# PIC32MX695F512L register map
Registers are 32-bit, access not given, reset 0x0 unless marked. A register's access mark holds for its fields unless they carry their own. Offsets are from the block's base; [hi:lo] are bit positions; 'fields as' and 'values as' point back to an identical list.

## CVR — CVR peripheral
Base 0xBF809800
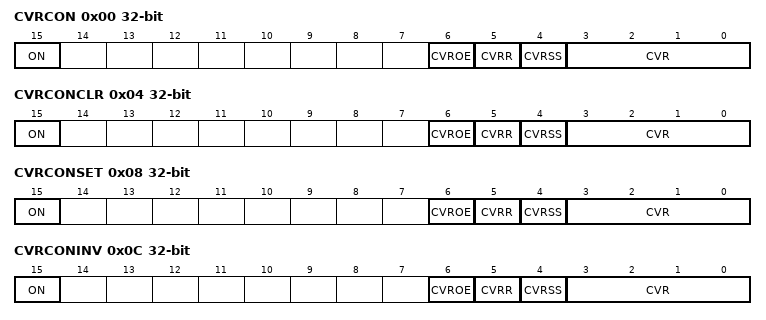
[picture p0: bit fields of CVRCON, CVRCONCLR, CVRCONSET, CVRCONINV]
0x00 CVRCON
  [15] ON, [6] CVROE, [5] CVRR, [4] CVRSS, [3:0] CVR
0x04 CVRCONCLR
  [15] ON, [6] CVROE, [5] CVRR, [4] CVRSS, [3:0] CVR
0x08 CVRCONSET
  [15] ON, [6] CVROE, [5] CVRR, [4] CVRSS, [3:0] CVR
0x0C CVRCONINV
  [15] ON, [6] CVROE, [5] CVRR, [4] CVRSS, [3:0] CVR

## CMP1 — CMP1 peripheral
Base 0xBF80A000
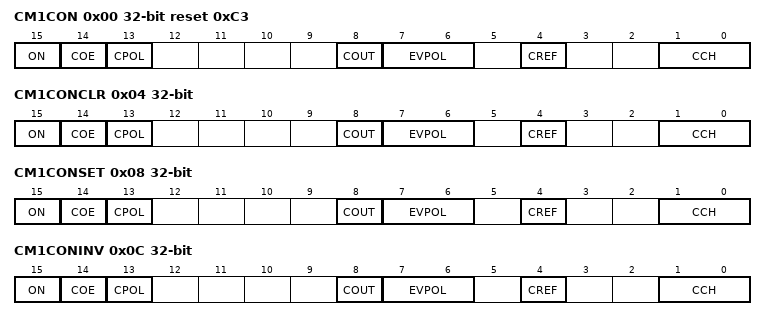
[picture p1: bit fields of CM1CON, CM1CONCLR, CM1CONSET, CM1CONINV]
0x00 CM1CON reset 0xC3
  [15] ON, [14] COE, [13] CPOL, [8] COUT, [7:6] EVPOL, [4] CREF, [1:0] CCH
0x04 CM1CONCLR
  fields as CM1CON
0x08 CM1CONSET
  fields as CM1CON
0x0C CM1CONINV
  fields as CM1CON

## CMP2 — CMP2 peripheral
Base 0xBF80A010
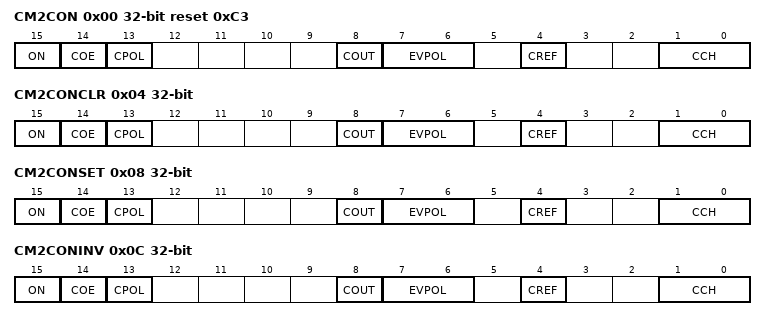
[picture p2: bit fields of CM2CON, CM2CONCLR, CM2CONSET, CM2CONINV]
0x00 CM2CON reset 0xC3
  [15] ON, [14] COE, [13] CPOL, [8] COUT, [7:6] EVPOL, [4] CREF, [1:0] CCH
0x04 CM2CONCLR
  fields as CM2CON
0x08 CM2CONSET
  fields as CM2CON
0x0C CM2CONINV
  fields as CM2CON

## CMP — CMP peripheral
Base 0xBF80A060
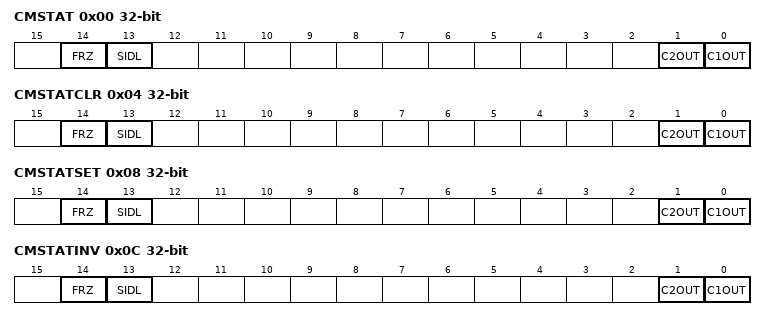
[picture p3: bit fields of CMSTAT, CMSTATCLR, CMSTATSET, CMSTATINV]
0x00 CMSTAT
  [14] FRZ, [13] SIDL, [1] C2OUT, [0] C1OUT
0x04 CMSTATCLR
  [14] FRZ, [13] SIDL, [1] C2OUT, [0] C1OUT
0x08 CMSTATSET
  [14] FRZ, [13] SIDL, [1] C2OUT, [0] C1OUT
0x0C CMSTATINV
  [14] FRZ, [13] SIDL, [1] C2OUT, [0] C1OUT

## OSC — OSC peripheral
Base 0xBF80F000
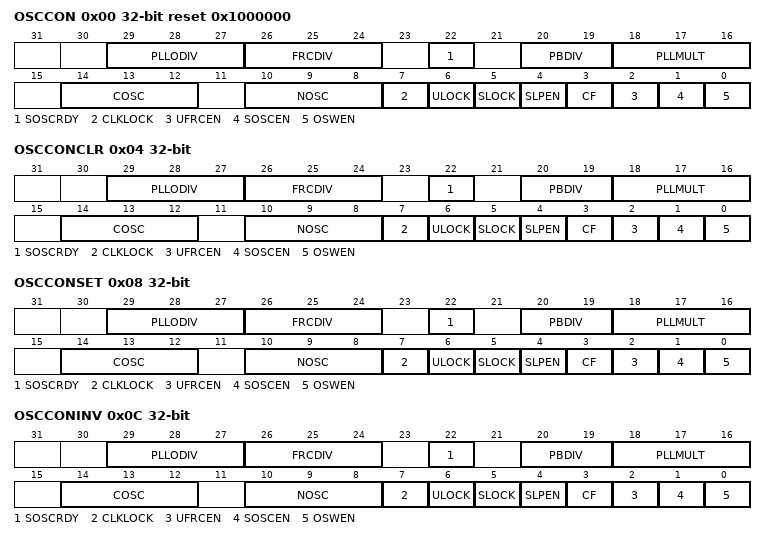
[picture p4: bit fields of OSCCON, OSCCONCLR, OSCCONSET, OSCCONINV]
0x00 OSCCON reset 0x1000000
  [29:27] PLLODIV, [26:24] FRCDIV, [22] SOSCRDY, [20:19] PBDIV, [18:16] PLLMULT, [14:12] COSC, [10:8] NOSC, [7] CLKLOCK, [6] ULOCK, [5] SLOCK, [4] SLPEN, [3] CF, [2] UFRCEN, [1] SOSCEN, [0] OSWEN
0x04 OSCCONCLR
  fields as OSCCON
0x08 OSCCONSET
  fields as OSCCON
0x0C OSCCONINV
  fields as OSCCON
0x10 OSCTUN
  [5:0] TUN
0x14 OSCTUNCLR
  [5:0] TUN
0x18 OSCTUNSET
  [5:0] TUN
0x1C OSCTUNINV
  [5:0] TUN

## CFG — CFG peripheral
Base 0xBF80F200
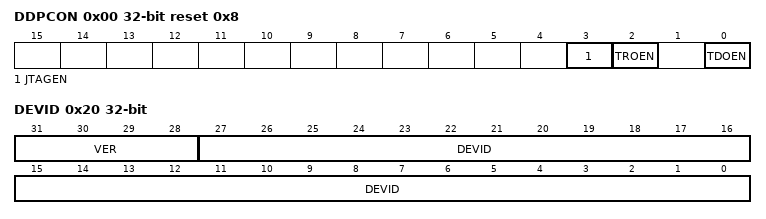
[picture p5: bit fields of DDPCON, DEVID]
0x00 DDPCON reset 0x8
  [3] JTAGEN, [2] TROEN, [0] TDOEN
0x20 DEVID
  [31:28] VER, [27:0] DEVID
0x30 SYSKEY
0x34 SYSKEYCLR
  [31:0] SYSKEY
0x38 SYSKEYSET
  [31:0] SYSKEY
0x3C SYSKEYINV
  [31:0] SYSKEY

## NVM — NVM peripheral
Base 0xBF80F400
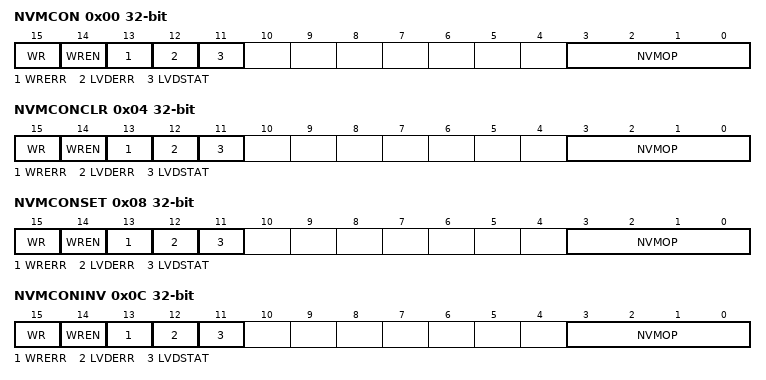
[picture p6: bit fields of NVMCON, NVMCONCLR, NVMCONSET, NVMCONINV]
0x00 NVMCON
  [15] WR, [14] WREN, [13] WRERR, [12] LVDERR, [11] LVDSTAT, [3:0] NVMOP
0x04 NVMCONCLR
  fields as NVMCON
0x08 NVMCONSET
  fields as NVMCON
0x0C NVMCONINV
  fields as NVMCON
0x10 NVMKEY
0x20 NVMADDR
0x24 NVMADDRCLR
  [31:0] NVMADDR
0x28 NVMADDRSET
  [31:0] NVMADDR
0x2C NVMADDRINV
  [31:0] NVMADDR
0x30 NVMDATA
0x40 NVMSRCADDR

## RCON — RCON peripheral
Base 0xBF80F600
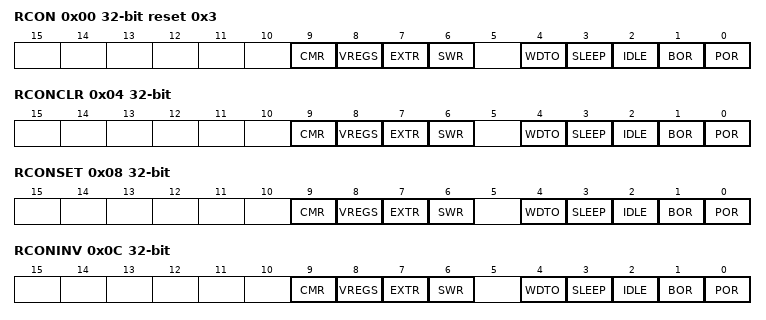
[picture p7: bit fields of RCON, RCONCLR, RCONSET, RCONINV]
0x00 RCON reset 0x3
  [9] CMR, [8] VREGS, [7] EXTR, [6] SWR, [4] WDTO, [3] SLEEP, [2] IDLE, [1] BOR, [0] POR
0x04 RCONCLR
  fields as RCON
0x08 RCONSET
  fields as RCON
0x0C RCONINV
  fields as RCON
0x10 RSWRST
  [0] SWRST
0x14 RSWRSTCLR
  [0] SWRST
0x18 RSWRSTSET
  [0] SWRST
0x1C RSWRSTINV
  [0] SWRST

## _DDPSTAT — _DDPSTAT peripheral
Base 0xBF880140
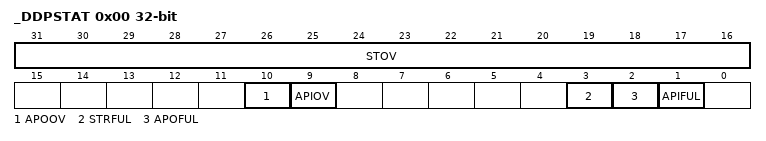
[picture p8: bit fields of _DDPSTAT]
0x00 _DDPSTAT
  [31:16] STOV, [10] APOOV, [9] APIOV, [3] STRFUL, [2] APOFUL, [1] APIFUL

## _STRO — _STRO peripheral
Base 0xBF880170
0x00 _STRO
0x04 _STROCLR
  [31:0] _STRO
0x08 _STROSET
  [31:0] _STRO
0x0C _STROINV
  [31:0] _STRO

## _APPO — _APPO peripheral
Base 0xBF880180
Registers as _STRO (with _STRO read as _APPO).

## _APPI — _APPI peripheral
Base 0xBF880190
0x00 _APPI

## BMX — BMX peripheral
Base 0xBF882000
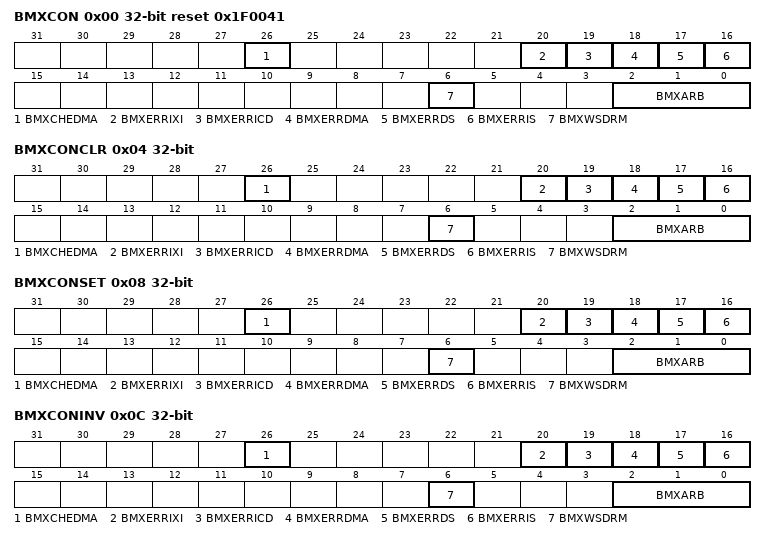
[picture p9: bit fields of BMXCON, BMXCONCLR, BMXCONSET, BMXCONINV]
0x00 BMXCON reset 0x1F0041
  [26] BMXCHEDMA, [20] BMXERRIXI, [19] BMXERRICD, [18] BMXERRDMA, [17] BMXERRDS, [16] BMXERRIS, [6] BMXWSDRM, [2:0] BMXARB
0x04 BMXCONCLR
  fields as BMXCON
0x08 BMXCONSET
  fields as BMXCON
0x0C BMXCONINV
  fields as BMXCON
0x10 BMXDKPBA
0x14 BMXDKPBACLR
  [31:0] BMXDKPBA
0x18 BMXDKPBASET
  [31:0] BMXDKPBA
0x1C BMXDKPBAINV
  [31:0] BMXDKPBA
0x20 BMXDUDBA
0x24 BMXDUDBACLR
  [31:0] BMXDUDBA
0x28 BMXDUDBASET
  [31:0] BMXDUDBA
0x2C BMXDUDBAINV
  [31:0] BMXDUDBA
0x30 BMXDUPBA
0x34 BMXDUPBACLR
  [31:0] BMXDUPBA
0x38 BMXDUPBASET
  [31:0] BMXDUPBA
0x3C BMXDUPBAINV
  [31:0] BMXDUPBA
0x40 BMXDRMSZ reset 0x20000
0x50 BMXPUPBA
0x54 BMXPUPBACLR
  [31:0] BMXPUPBA
0x58 BMXPUPBASET
  [31:0] BMXPUPBA
0x5C BMXPUPBAINV
  [31:0] BMXPUPBA
0x60 BMXPFMSZ reset 0x80000
0x70 BMXBOOTSZ reset 0x3000
